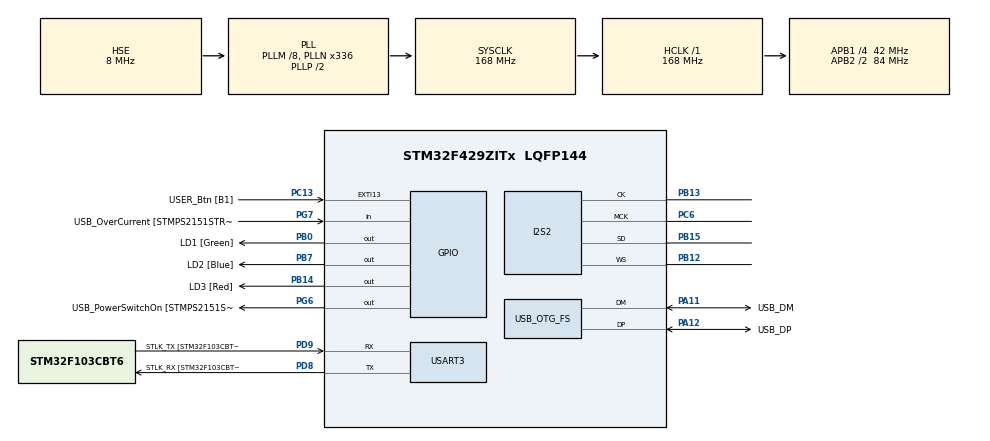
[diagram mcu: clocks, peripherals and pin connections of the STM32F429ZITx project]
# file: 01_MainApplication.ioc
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Dma.Request0=SPI2_TX
Dma.SPI2_TX.0.Direction=DMA_MEMORY_TO_PERIPH
Dma.SPI2_TX.0.FIFOMode=DMA_FIFOMODE_ENABLE
Dma.SPI2_TX.0.FIFOThreshold=DMA_FIFO_THRESHOLD_FULL
Dma.SPI2_TX.0.Instance=DMA1_Stream4
Dma.SPI2_TX.0.MemBurst=DMA_MBURST_SINGLE
Dma.SPI2_TX.0.MemDataAlignment=DMA_MDATAALIGN_HALFWORD
Dma.SPI2_TX.0.MemInc=DMA_MINC_ENABLE
Dma.SPI2_TX.0.Mode=DMA_CIRCULAR
Dma.SPI2_TX.0.PeriphBurst=DMA_PBURST_SINGLE
Dma.SPI2_TX.0.PeriphDataAlignment=DMA_PDATAALIGN_HALFWORD
Dma.SPI2_TX.0.PeriphInc=DMA_PINC_DISABLE
Dma.SPI2_TX.0.Priority=DMA_PRIORITY_LOW
I2S2.AudioFreq=I2S_AUDIOFREQ_44K
I2S2.CPOL=I2S_CPOL_HIGH
I2S2.DataFormat=I2S_DATAFORMAT_16B
I2S2.ErrorAudioFreq=0.24 %
I2S2.FullDuplexMode=I2S_FULLDUPLEXMODE_DISABLE
I2S2.Instance=SPI$Index
I2S2.RealAudioFreq=44.108 KHz
I2S2.VirtualMode=I2S_MODE_MASTER
Mcu.Family=STM32F4
Mcu.Name=STM32F429ZITx
Mcu.Package=LQFP144
NVIC.DMA1_Stream4_IRQn=true\:0\:0\:false\:false\:true\:false\:true
NVIC.OTG_FS_IRQn=true\:0\:0\:false\:false\:true\:false\:true
NVIC.PriorityGroup=NVIC_PRIORITYGROUP_4
NVIC.TIM2_IRQn=true\:0\:0\:false\:false\:true\:true\:true
PA10.GPIO_Label=USB_ID
PA10.Signal=USB_OTG_FS_ID
PA11.GPIO_Label=USB_DM
PA11.Mode=Host_Only
PA11.Signal=USB_OTG_FS_DM
PA12.GPIO_Label=USB_DP
PA12.Mode=Host_Only
PA12.Signal=USB_OTG_FS_DP
PA13.GPIO_Label=TMS
PA13.Mode=Serial_Wire
PA13.Signal=SYS_JTMS-SWDIO
PA14.GPIO_Label=TCK
PA14.Mode=Serial_Wire
PA14.Signal=SYS_JTCK-SWCLK
PA8.GPIO_Label=USB_SOF [TP1]
PA8.Signal=USB_OTG_FS_SOF
PA9.GPIO_Label=USB_VBUS
PA9.Signal=USB_OTG_FS_VBUS
PB0.GPIO_Label=LD1 [Green]
PB0.Signal=GPIO_Output
PB12.Mode=Half_Duplex_Master
PB12.Signal=I2S2_WS
PB13.Mode=Half_Duplex_Master
PB13.Signal=I2S2_CK
PB14.GPIO_Label=LD3 [Red]
PB14.Signal=GPIO_Output
PB15.Mode=Half_Duplex_Master
PB15.Signal=I2S2_SD
PB7.GPIO_Label=LD2 [Blue]
PB7.Signal=GPIO_Output
PC13.GPIO_Label=USER_Btn [B1]
PC13.Signal=GPXTI13
PC14/OSC32_IN.Mode=LSE-External-Oscillator
PC14/OSC32_IN.Signal=RCC_OSC32_IN
PC15/OSC32_OUT.Mode=LSE-External-Oscillator
PC15/OSC32_OUT.Signal=RCC_OSC32_OUT
PC6.Mode=Master_Clock_Activated
PC6.Signal=I2S2_MCK
PD8.GPIO_Label=STLK_RX [STM32F103CBT6_PA3]
PD8.Mode=Asynchronous
PD8.Signal=USART3_TX
PD9.GPIO_Label=STLK_TX [STM32F103CBT6_PA2]
PD9.Mode=Asynchronous
PD9.Signal=USART3_RX
PG6.GPIO_Label=USB_PowerSwitchOn [STMPS2151STR_EN]
PG6.Signal=GPIO_Output
PG7.GPIO_Label=USB_OverCurrent [STMPS2151STR_FAULT]
PG7.Signal=GPIO_Input
PH0/OSC_IN.GPIO_Label=MCO [STM32F103CBT6_PA8]
PH0/OSC_IN.Mode=HSE-External-Clock-Source
PH0/OSC_IN.Signal=RCC_OSC_IN
PH1/OSC_OUT.Mode=HSE-External-Clock-Source
PH1/OSC_OUT.Signal=RCC_OSC_OUT
ProjectManager.HeapSize=0x2000
ProjectManager.StackSize=0x2000
ProjectManager.TargetToolchain=STM32CubeIDE
RCC.48MHZClocksFreq_Value=48000000
RCC.AHBFreq_Value=168000000
RCC.APB1CLKDivider=RCC_HCLK_DIV4
RCC.APB1Freq_Value=42000000
RCC.APB1TimFreq_Value=84000000
RCC.APB2CLKDivider=RCC_HCLK_DIV2
RCC.APB2Freq_Value=84000000
RCC.APB2TimFreq_Value=168000000
RCC.CortexFreq_Value=168000000
RCC.HCLKFreq_Value=168000000
RCC.HSE_VALUE=8000000
RCC.HSI_VALUE=16000000
RCC.PLLI2SN=271
RCC.PLLI2SR=6
RCC.PLLM=8
RCC.PLLMUL=RCC_PLL_MUL9
RCC.PLLN=336
RCC.PLLQ=7
RCC.PRESCALERUSB=RCC_USBCLKSOURCE_PLL_DIV1_5
RCC.SYSCLKFreq_VALUE=168000000
RCC.SYSCLKSource=RCC_SYSCLKSOURCE_PLLCLK
RCC.SYSCLKSourceVirtual=RCC_SYSCLKSOURCE_PLLCLK
RCC.USBFreq_Value=48000000
RCC.VCOOutputFreq_Value=336000000
TIM2.Period=20-1
TIM2.Prescaler=84-1
TIM2.TIM_MasterOutputTrigger=TIM_TRGO_UPDATE
USART3.VirtualMode=VM_ASYNC
USB_HOST.USBH_HandleTypeDef-MSC_FS=hUsbHostFS
USB_HOST.VirtualModeFS=Msc
USB_OTG_FS.VirtualMode=Host_Only
USB_OTG_FS.phy_itface=HCD_PHY_EMBEDDED
VP_FATFS_VS_USB.Mode=USB
VP_TIM2_VS_ClockSourceINT.Mode=Internal
VP_USB_HOST_VS_USB_HOST_MSC_FS.Mode=MSC_FS
board=NUCLEO-F429ZI

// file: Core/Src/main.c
/* USER CODE BEGIN Header */
/**
  ******************************************************************************
  * @file           : main.c
  * @brief          : Main program body
  ******************************************************************************
  * @attention
  *
  * <h2><center>&copy; Copyright (c) 2020 STMicroelectronics.
  * All rights reserved.</center></h2>
  *
  * This software component is licensed by ST under Ultimate Liberty license
  * SLA0044, the "License"; You may not use this file except in compliance with
  * the License. You may obtain a copy of the License at:
  *                             www.st.com/SLA0044
  *
  ******************************************************************************
  */
/* USER CODE END Header */
#include "main.h"
#include "fatfs.h"
#include "usb_host.h"

I2S_HandleTypeDef hi2s2;
DMA_HandleTypeDef hdma_spi2_tx;

TIM_HandleTypeDef htim2;

UART_HandleTypeDef huart3;

void SystemClock_Config(void);
static void MX_GPIO_Init(void);
static void MX_DMA_Init(void);
static void MX_USART3_UART_Init(void);
static void MX_I2S2_Init(void);
static void MX_TIM2_Init(void);
void MX_USB_HOST_Process(void);

int main(void)
{

  /* USER CODE BEGIN 1 */
//	const int c1 __attribute__((at(0x10000))) = 1; /* RO */
//	const int c2 __attribute__((at(0x10001))) = 2; /* RO */
//	const int c3 __attribute__((at(0x10002))) = 3; /* RO */
//	const int c4 __attribute__((at(0x10003))) = 4; /* RO */
//	const int descriptor[3] __attribute__((__at__0x0)) = { 1,2,3 };
  /* USER CODE END 1 */

  /* MCU Configuration--------------------------------------------------------*/

  /* Reset of all peripherals, Initializes the Flash interface and the Systick. */
  HAL_Init();

  /* Configure the system clock */
  SystemClock_Config();

  /* Initialize all configured peripherals */
  MX_GPIO_Init();
  MX_DMA_Init();
  MX_USART3_UART_Init();
  MX_I2S2_Init();
  MX_TIM2_Init();
  MX_FATFS_Init();
  MX_USB_HOST_Init();
  /* USER CODE BEGIN 2 */
  HAL_GPIO_WritePin(GPIOG, GPIO_PIN_6, GPIO_PIN_SET);
  HAL_UART_Transmit(&huart3, "SileliS radio main app\r\n", 24, 100);
  /* USER CODE END 2 */

  /* Infinite loop */
  while (1)
  {
    MX_USB_HOST_Process();

    /* USER CODE BEGIN 3 */
  };
  /* USER CODE END 3 */
}

void SystemClock_Config(void)
{
  RCC_OscInitTypeDef RCC_OscInitStruct = {0};
  RCC_ClkInitTypeDef RCC_ClkInitStruct = {0};
  RCC_PeriphCLKInitTypeDef PeriphClkInitStruct = {0};

  /** Configure the main internal regulator output voltage
  */
  __HAL_RCC_PWR_CLK_ENABLE();
  __HAL_PWR_VOLTAGESCALING_CONFIG(PWR_REGULATOR_VOLTAGE_SCALE1);
  /** Initializes the RCC Oscillators according to the specified parameters
  * in the RCC_OscInitTypeDef structure.
  */
  RCC_OscInitStruct.OscillatorType = RCC_OSCILLATORTYPE_HSE;
  RCC_OscInitStruct.HSEState = RCC_HSE_BYPASS;
  RCC_OscInitStruct.PLL.PLLState = RCC_PLL_ON;
  RCC_OscInitStruct.PLL.PLLSource = RCC_PLLSOURCE_HSE;
  RCC_OscInitStruct.PLL.PLLM = 8;
  RCC_OscInitStruct.PLL.PLLN = 336;
  RCC_OscInitStruct.PLL.PLLP = RCC_PLLP_DIV2;
  RCC_OscInitStruct.PLL.PLLQ = 7;
  if (HAL_RCC_OscConfig(&RCC_OscInitStruct) != HAL_OK)
  {
    Error_Handler();
  }
  /** Initializes the CPU, AHB and APB buses clocks
  */
  RCC_ClkInitStruct.ClockType = RCC_CLOCKTYPE_HCLK|RCC_CLOCKTYPE_SYSCLK
                              |RCC_CLOCKTYPE_PCLK1|RCC_CLOCKTYPE_PCLK2;
  RCC_ClkInitStruct.SYSCLKSource = RCC_SYSCLKSOURCE_PLLCLK;
  RCC_ClkInitStruct.AHBCLKDivider = RCC_SYSCLK_DIV1;
  RCC_ClkInitStruct.APB1CLKDivider = RCC_HCLK_DIV4;
  RCC_ClkInitStruct.APB2CLKDivider = RCC_HCLK_DIV2;

  if (HAL_RCC_ClockConfig(&RCC_ClkInitStruct, FLASH_LATENCY_5) != HAL_OK)
  {
    Error_Handler();
  }
  PeriphClkInitStruct.PeriphClockSelection = RCC_PERIPHCLK_I2S;
  PeriphClkInitStruct.PLLI2S.PLLI2SN = 271;
  PeriphClkInitStruct.PLLI2S.PLLI2SR = 6;
  if (HAL_RCCEx_PeriphCLKConfig(&PeriphClkInitStruct) != HAL_OK)
  {
    Error_Handler();
  }
}

static void MX_I2S2_Init(void)
{

  hi2s2.Instance = SPI2;
  hi2s2.Init.Mode = I2S_MODE_MASTER_TX;
  hi2s2.Init.Standard = I2S_STANDARD_PHILIPS;
  hi2s2.Init.DataFormat = I2S_DATAFORMAT_16B;
  hi2s2.Init.MCLKOutput = I2S_MCLKOUTPUT_ENABLE;
  hi2s2.Init.AudioFreq = I2S_AUDIOFREQ_44K;
  hi2s2.Init.CPOL = I2S_CPOL_HIGH;
  hi2s2.Init.ClockSource = I2S_CLOCK_PLL;
  hi2s2.Init.FullDuplexMode = I2S_FULLDUPLEXMODE_DISABLE;
  if (HAL_I2S_Init(&hi2s2) != HAL_OK)
  {
    Error_Handler();
  }

}

static void MX_TIM2_Init(void)
{

  TIM_ClockConfigTypeDef sClockSourceConfig = {0};
  TIM_MasterConfigTypeDef sMasterConfig = {0};

  htim2.Instance = TIM2;
  htim2.Init.Prescaler = 84-1;
  htim2.Init.CounterMode = TIM_COUNTERMODE_UP;
  htim2.Init.Period = 20-1;
  htim2.Init.ClockDivision = TIM_CLOCKDIVISION_DIV1;
  htim2.Init.AutoReloadPreload = TIM_AUTORELOAD_PRELOAD_DISABLE;
  if (HAL_TIM_Base_Init(&htim2) != HAL_OK)
  {
    Error_Handler();
  }
  sClockSourceConfig.ClockSource = TIM_CLOCKSOURCE_INTERNAL;
  if (HAL_TIM_ConfigClockSource(&htim2, &sClockSourceConfig) != HAL_OK)
  {
    Error_Handler();
  }
  sMasterConfig.MasterOutputTrigger = TIM_TRGO_UPDATE;
  sMasterConfig.MasterSlaveMode = TIM_MASTERSLAVEMODE_DISABLE;
  if (HAL_TIMEx_MasterConfigSynchronization(&htim2, &sMasterConfig) != HAL_OK)
  {
    Error_Handler();
  }

}

static void MX_USART3_UART_Init(void)
{

  huart3.Instance = USART3;
  huart3.Init.BaudRate = 115200;
  huart3.Init.WordLength = UART_WORDLENGTH_8B;
  huart3.Init.StopBits = UART_STOPBITS_1;
  huart3.Init.Parity = UART_PARITY_NONE;
  huart3.Init.Mode = UART_MODE_TX_RX;
  huart3.Init.HwFlowCtl = UART_HWCONTROL_NONE;
  huart3.Init.OverSampling = UART_OVERSAMPLING_16;
  if (HAL_UART_Init(&huart3) != HAL_OK)
  {
    Error_Handler();
  }

}

static void MX_DMA_Init(void)
{

  /* DMA controller clock enable */
  __HAL_RCC_DMA1_CLK_ENABLE();

  /* DMA interrupt init */
  /* DMA1_Stream4_IRQn interrupt configuration */
  HAL_NVIC_SetPriority(DMA1_Stream4_IRQn, 0, 0);
  HAL_NVIC_EnableIRQ(DMA1_Stream4_IRQn);

}

static void MX_GPIO_Init(void)
{
  GPIO_InitTypeDef GPIO_InitStruct = {0};

  /* GPIO Ports Clock Enable */
  __HAL_RCC_GPIOE_CLK_ENABLE();
  __HAL_RCC_GPIOC_CLK_ENABLE();
  __HAL_RCC_GPIOF_CLK_ENABLE();
  __HAL_RCC_GPIOH_CLK_ENABLE();
  __HAL_RCC_GPIOA_CLK_ENABLE();
  __HAL_RCC_GPIOB_CLK_ENABLE();
  __HAL_RCC_GPIOG_CLK_ENABLE();
  __HAL_RCC_GPIOD_CLK_ENABLE();

  /*Configure GPIO pin Output Level */
  HAL_GPIO_WritePin(GPIOB, LD1_Pin|LD3_Pin|LD2_Pin, GPIO_PIN_RESET);

  /*Configure GPIO pin Output Level */
  HAL_GPIO_WritePin(USB_PowerSwitchOn_GPIO_Port, USB_PowerSwitchOn_Pin, GPIO_PIN_RESET);

  /*Configure GPIO pins : PE2 PE3 PE4 PE5
                           PE6 PE7 PE8 PE9
                           PE10 PE11 PE12 PE13
                           PE14 PE15 PE0 PE1 */
  GPIO_InitStruct.Pin = GPIO_PIN_2|GPIO_PIN_3|GPIO_PIN_4|GPIO_PIN_5
                          |GPIO_PIN_6|GPIO_PIN_7|GPIO_PIN_8|GPIO_PIN_9
                          |GPIO_PIN_10|GPIO_PIN_11|GPIO_PIN_12|GPIO_PIN_13
                          |GPIO_PIN_14|GPIO_PIN_15|GPIO_PIN_0|GPIO_PIN_1;
  GPIO_InitStruct.Mode = GPIO_MODE_ANALOG;
  GPIO_InitStruct.Pull = GPIO_NOPULL;
  HAL_GPIO_Init(GPIOE, &GPIO_InitStruct);

  /*Configure GPIO pin : USER_Btn_Pin */
  GPIO_InitStruct.Pin = USER_Btn_Pin;
  GPIO_InitStruct.Mode = GPIO_MODE_IT_RISING;
  GPIO_InitStruct.Pull = GPIO_NOPULL;
  HAL_GPIO_Init(USER_Btn_GPIO_Port, &GPIO_InitStruct);

  /*Configure GPIO pins : PF0 PF1 PF2 PF3
                           PF4 PF5 PF6 PF7
                           PF8 PF9 PF10 PF11
                           PF12 PF13 PF14 PF15 */
  GPIO_InitStruct.Pin = GPIO_PIN_0|GPIO_PIN_1|GPIO_PIN_2|GPIO_PIN_3
                          |GPIO_PIN_4|GPIO_PIN_5|GPIO_PIN_6|GPIO_PIN_7
                          |GPIO_PIN_8|GPIO_PIN_9|GPIO_PIN_10|GPIO_PIN_11
                          |GPIO_PIN_12|GPIO_PIN_13|GPIO_PIN_14|GPIO_PIN_15;
  GPIO_InitStruct.Mode = GPIO_MODE_ANALOG;
  GPIO_InitStruct.Pull = GPIO_NOPULL;
  HAL_GPIO_Init(GPIOF, &GPIO_InitStruct);

  /*Configure GPIO pins : PC0 PC1 PC2 PC3
                           PC4 PC5 PC7 PC8
                           PC9 PC10 PC11 PC12 */
  GPIO_InitStruct.Pin = GPIO_PIN_0|GPIO_PIN_1|GPIO_PIN_2|GPIO_PIN_3
                          |GPIO_PIN_4|GPIO_PIN_5|GPIO_PIN_7|GPIO_PIN_8
                          |GPIO_PIN_9|GPIO_PIN_10|GPIO_PIN_11|GPIO_PIN_12;
  GPIO_InitStruct.Mode = GPIO_MODE_ANALOG;
  GPIO_InitStruct.Pull = GPIO_NOPULL;
  HAL_GPIO_Init(GPIOC, &GPIO_InitStruct);

  /*Configure GPIO pins : PA0 PA1 PA2 PA3
                           PA4 PA5 PA6 PA7
                           PA15 */
  GPIO_InitStruct.Pin = GPIO_PIN_0|GPIO_PIN_1|GPIO_PIN_2|GPIO_PIN_3
                          |GPIO_PIN_4|GPIO_PIN_5|GPIO_PIN_6|GPIO_PIN_7
                          |GPIO_PIN_15;
  GPIO_InitStruct.Mode = GPIO_MODE_ANALOG;
  GPIO_InitStruct.Pull = GPIO_NOPULL;
  HAL_GPIO_Init(GPIOA, &GPIO_InitStruct);

  /*Configure GPIO pins : LD1_Pin LD3_Pin LD2_Pin */
  GPIO_InitStruct.Pin = LD1_Pin|LD3_Pin|LD2_Pin;
  GPIO_InitStruct.Mode = GPIO_MODE_OUTPUT_PP;
  GPIO_InitStruct.Pull = GPIO_NOPULL;
  GPIO_InitStruct.Speed = GPIO_SPEED_FREQ_LOW;
  HAL_GPIO_Init(GPIOB, &GPIO_InitStruct);

  /*Configure GPIO pins : PB1 PB2 PB10 PB11
                           PB3 PB4 PB5 PB6
                           PB8 PB9 */
  GPIO_InitStruct.Pin = GPIO_PIN_1|GPIO_PIN_2|GPIO_PIN_10|GPIO_PIN_11
                          |GPIO_PIN_3|GPIO_PIN_4|GPIO_PIN_5|GPIO_PIN_6
                          |GPIO_PIN_8|GPIO_PIN_9;
  GPIO_InitStruct.Mode = GPIO_MODE_ANALOG;
  GPIO_InitStruct.Pull = GPIO_NOPULL;
  HAL_GPIO_Init(GPIOB, &GPIO_InitStruct);

  /*Configure GPIO pins : PG0 PG1 PG2 PG3
                           PG4 PG5 PG8 PG9
                           PG10 PG11 PG12 PG13
                           PG14 PG15 */
  GPIO_InitStruct.Pin = GPIO_PIN_0|GPIO_PIN_1|GPIO_PIN_2|GPIO_PIN_3
                          |GPIO_PIN_4|GPIO_PIN_5|GPIO_PIN_8|GPIO_PIN_9
                          |GPIO_PIN_10|GPIO_PIN_11|GPIO_PIN_12|GPIO_PIN_13
                          |GPIO_PIN_14|GPIO_PIN_15;
  GPIO_InitStruct.Mode = GPIO_MODE_ANALOG;
  GPIO_InitStruct.Pull = GPIO_NOPULL;
  HAL_GPIO_Init(GPIOG, &GPIO_InitStruct);

  /*Configure GPIO pins : PD10 PD11 PD12 PD13
                           PD14 PD15 PD0 PD1
                           PD2 PD3 PD4 PD5
                           PD6 PD7 */
  GPIO_InitStruct.Pin = GPIO_PIN_10|GPIO_PIN_11|GPIO_PIN_12|GPIO_PIN_13
                          |GPIO_PIN_14|GPIO_PIN_15|GPIO_PIN_0|GPIO_PIN_1
                          |GPIO_PIN_2|GPIO_PIN_3|GPIO_PIN_4|GPIO_PIN_5
                          |GPIO_PIN_6|GPIO_PIN_7;
  GPIO_InitStruct.Mode = GPIO_MODE_ANALOG;
  GPIO_InitStruct.Pull = GPIO_NOPULL;
  HAL_GPIO_Init(GPIOD, &GPIO_InitStruct);

  /*Configure GPIO pin : USB_PowerSwitchOn_Pin */
  GPIO_InitStruct.Pin = USB_PowerSwitchOn_Pin;
  GPIO_InitStruct.Mode = GPIO_MODE_OUTPUT_PP;
  GPIO_InitStruct.Pull = GPIO_NOPULL;
  GPIO_InitStruct.Speed = GPIO_SPEED_FREQ_LOW;
  HAL_GPIO_Init(USB_PowerSwitchOn_GPIO_Port, &GPIO_InitStruct);

  /*Configure GPIO pin : USB_OverCurrent_Pin */
  GPIO_InitStruct.Pin = USB_OverCurrent_Pin;
  GPIO_InitStruct.Mode = GPIO_MODE_INPUT;
  GPIO_InitStruct.Pull = GPIO_NOPULL;
  HAL_GPIO_Init(USB_OverCurrent_GPIO_Port, &GPIO_InitStruct);

}

void Error_Handler(void)
{
}

/************************ (C) COPYRIGHT STMicroelectronics *****END OF FILE****/
